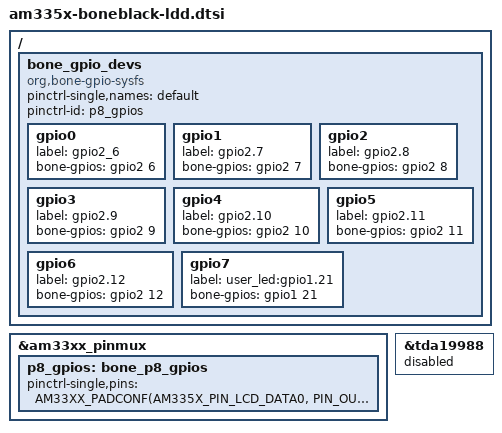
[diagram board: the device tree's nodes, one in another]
/ {
	bone_gpio_devs {
		compatible="org,bone-gpio-sysfs";
		pinctrl-single,names = "default";
		pinctrl-id = <&p8_gpios>;
		gpio0 {
			label = "gpio2_6";
			bone-gpios = <&gpio2 6 GPIO_ACTIVE_HIGH>;
		};
		gpio1 {
			label = "gpio2.7";
			bone-gpios = <&gpio2 7 GPIO_ACTIVE_HIGH>;
		};
		gpio2 {
			label = "gpio2.8";
			bone-gpios = <&gpio2 8 GPIO_ACTIVE_HIGH>;
		};
		gpio3 {
			label = "gpio2.9";
			bone-gpios = <&gpio2 9 GPIO_ACTIVE_HIGH>;
		};
		gpio4 {
			label = "gpio2.10";
			bone-gpios = <&gpio2 10 GPIO_ACTIVE_HIGH>;
		};
		gpio5 {
			label = "gpio2.11";
			bone-gpios = <&gpio2 11 GPIO_ACTIVE_HIGH>;
		};
		gpio6 {
			label = "gpio2.12";
			bone-gpios = <&gpio2 12 GPIO_ACTIVE_HIGH>;
		};
		gpio7 {
			label = "user_led:gpio1.21";
			bone-gpios = <&gpio1 21 GPIO_ACTIVE_HIGH>;
		};
	};
};

&am33xx_pinmux {
	p8_gpios: bone_p8_gpios {
		pinctrl-single,pins = <
			AM33XX_PADCONF(AM335X_PIN_LCD_DATA0, PIN_OUTPUT, MUX_MODE7)
			AM33XX_PADCONF(AM335X_PIN_LCD_DATA1, PIN_OUTPUT, MUX_MODE7)
			AM33XX_PADCONF(AM335X_PIN_LCD_DATA2, PIN_OUTPUT, MUX_MODE7)
			AM33XX_PADCONF(AM335X_PIN_LCD_DATA3, PIN_OUTPUT, MUX_MODE7)
			AM33XX_PADCONF(AM335X_PIN_LCD_DATA4, PIN_OUTPUT, MUX_MODE7)
			AM33XX_PADCONF(AM335X_PIN_LCD_DATA5, PIN_OUTPUT, MUX_MODE7)
			AM33XX_PADCONF(AM335X_PIN_LCD_DATA6, PIN_OUTPUT, MUX_MODE7)
		>;
	};
};

&tda19988 {
	status = "disabled";
};
